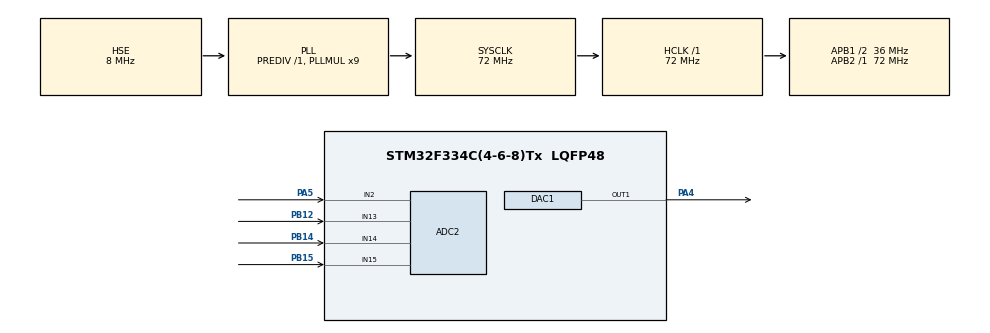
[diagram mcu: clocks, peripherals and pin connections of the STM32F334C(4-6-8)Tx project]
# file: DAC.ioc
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ADC2.Channel-0\#ChannelRegularConversion=ADC_CHANNEL_2
ADC2.NbrOfConversionFlag=1
ADC2.Offset-0\#ChannelRegularConversion=0
ADC2.OffsetNumber-0\#ChannelRegularConversion=ADC_OFFSET_NONE
ADC2.Rank-0\#ChannelRegularConversion=1
ADC2.SamplingTime-0\#ChannelRegularConversion=ADC_SAMPLETIME_1CYCLE_5
ADC2.SubFamily=STM32F334x8
Dma.ADC2.0.Direction=DMA_PERIPH_TO_MEMORY
Dma.ADC2.0.Instance=DMA1_Channel2
Dma.ADC2.0.MemDataAlignment=DMA_MDATAALIGN_HALFWORD
Dma.ADC2.0.MemInc=DMA_MINC_ENABLE
Dma.ADC2.0.Mode=DMA_NORMAL
Dma.ADC2.0.PeriphDataAlignment=DMA_PDATAALIGN_HALFWORD
Dma.ADC2.0.PeriphInc=DMA_PINC_DISABLE
Dma.ADC2.0.Priority=DMA_PRIORITY_HIGH
Dma.Request0=ADC2
Mcu.Family=STM32F3
Mcu.Name=STM32F334C(4-6-8)Tx
Mcu.Package=LQFP48
NVIC.DMA1_Channel2_IRQn=true\:0\:0\:false\:false\:true\:false
NVIC.PriorityGroup=NVIC_PRIORITYGROUP_0
PA13.GPIO_Label=SWDIO
PA13.Mode=Serial_Wire
PA13.Signal=SYS_JTMS-SWDIO
PA14.GPIO_Label=SWCLK
PA14.Mode=Serial_Wire
PA14.Signal=SYS_JTCK-SWCLK
PA4.Signal=COMP_DAC11_group
PA5.Mode=IN2-Single-Ended
PA5.Signal=ADC2_IN2
PB12.Mode=IN13-Single-Ended
PB12.Signal=ADC2_IN13
PB14.Mode=IN14-Single-Ended
PB14.Signal=ADC2_IN14
PB15.Mode=IN15-Single-Ended
PB15.Signal=ADC2_IN15
PF0\ /\ OSC_IN.GPIO_Label=PF0-OSC_IN
PF0\ /\ OSC_IN.Mode=HSE-External-Oscillator
PF0\ /\ OSC_IN.Signal=RCC_OSC_IN
PF1\ /\ OSC_OUT.Mode=HSE-External-Oscillator
PF1\ /\ OSC_OUT.Signal=RCC_OSC_OUT
ProjectManager.HeapSize=0x200
ProjectManager.StackSize=0x400
ProjectManager.TargetToolchain=EWARM V7
RCC.AHBFreq_Value=72000000
RCC.APB1CLKDivider=RCC_HCLK_DIV2
RCC.APB1Freq_Value=36000000
RCC.APB1TimFreq_Value=72000000
RCC.APB2Freq_Value=72000000
RCC.APB2TimFreq_Value=72000000
RCC.CortexFreq_Value=72000000
RCC.HCLKFreq_Value=72000000
RCC.HSE_VALUE=8000000
RCC.HSI_VALUE=8000000
RCC.LSE_VALUE=32768
RCC.PLLMUL=RCC_PLL_MUL9
RCC.PLLSourceVirtual=RCC_PLLSOURCE_HSE
RCC.SYSCLKFreq_VALUE=72000000
RCC.SYSCLKSourceVirtual=RCC_SYSCLKSOURCE_PLLCLK
SH.COMP_DAC11_group.0=DAC1_OUT1,DAC_OUT1
board=32F3348DISCOVERY

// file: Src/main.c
/**
  ******************************************************************************
  * @file           : main.c
  * @brief          : Main program body
  ******************************************************************************
  ** This notice applies to any and all portions of this file
  * that are not between comment pairs USER CODE BEGIN and
  * USER CODE END. Other portions of this file, whether
  * inserted by the user or by software development tools
  * are owned by their respective copyright owners.
  *
  * COPYRIGHT(c) 2019 STMicroelectronics
  *
  * Redistribution and use in source and binary forms, with or without modification,
  * are permitted provided that the following conditions are met:
  *   1. Redistributions of source code must retain the above copyright notice,
  *      this list of conditions and the following disclaimer.
  *   2. Redistributions in binary form must reproduce the above copyright notice,
  *      this list of conditions and the following disclaimer in the documentation
  *      and/or other materials provided with the distribution.
  *   3. Neither the name of STMicroelectronics nor the names of its contributors
  *      may be used to endorse or promote products derived from this software
  *      without specific prior written permission.
  *
  * THIS SOFTWARE IS PROVIDED BY THE COPYRIGHT HOLDERS AND CONTRIBUTORS "AS IS"
  * AND ANY EXPRESS OR IMPLIED WARRANTIES, INCLUDING, BUT NOT LIMITED TO, THE
  * IMPLIED WARRANTIES OF MERCHANTABILITY AND FITNESS FOR A PARTICULAR PURPOSE ARE
  * DISCLAIMED. IN NO EVENT SHALL THE COPYRIGHT HOLDER OR CONTRIBUTORS BE LIABLE
  * FOR ANY DIRECT, INDIRECT, INCIDENTAL, SPECIAL, EXEMPLARY, OR CONSEQUENTIAL
  * DAMAGES (INCLUDING, BUT NOT LIMITED TO, PROCUREMENT OF SUBSTITUTE GOODS OR
  * SERVICES; LOSS OF USE, DATA, OR PROFITS; OR BUSINESS INTERRUPTION) HOWEVER
  * CAUSED AND ON ANY THEORY OF LIABILITY, WHETHER IN CONTRACT, STRICT LIABILITY,
  * OR TORT (INCLUDING NEGLIGENCE OR OTHERWISE) ARISING IN ANY WAY OUT OF THE USE
  * OF THIS SOFTWARE, EVEN IF ADVISED OF THE POSSIBILITY OF SUCH DAMAGE.
  *
  ******************************************************************************
  */
#include "main.h"
#include "stm32f3xx_hal.h"

/* USER CODE BEGIN Includes */
// This test includes 6 parts:
// 1. Test DAC
// 2. Test ADC-DMA with Sampling
// 3. Test GPIO input interrupt
// 4. Test System Stick Timer
// 5. Test UART
// 6. Test SPI

/* USER CODE END Includes */

ADC_HandleTypeDef hadc2;
DMA_HandleTypeDef hdma_adc2;

DAC_HandleTypeDef hdac1;

/* USER CODE BEGIN PV */
/* Private variables ---------------------------------------------------------*/
uint16_t adcValue = 0;
uint32_t i = 0;
/* USER CODE END PV */

void SystemClock_Config(void);
static void MX_GPIO_Init(void);
static void MX_DMA_Init(void);
static void MX_DAC1_Init(void);
static void MX_ADC2_Init(void);

/* USER CODE BEGIN PFP */
/* Private function prototypes -----------------------------------------------*/

/* USER CODE END PFP */

/* USER CODE BEGIN 0 */
// Input voltage must be x100 of desired value
void SetCurVolt( uint16_t x100voltage){
    uint16_t setValue;

    // 0 to 4095 leads to 0V -> 3.3V
    // setValue = (uint16_t)voltage/100/3.3*4096;
    setValue = (uint16_t)(x100voltage*12.412);

    //(#) 12-bit right alignment using DAC_ALIGN_12B_R
    HAL_DAC_SetValue(&hdac1, DAC_CHANNEL_1, DAC_ALIGN_12B_R, setValue);
    //HAL_Delay(1);
}
/* USER CODE END 0 */

int main(void)
{

  /* MCU Configuration----------------------------------------------------------*/

  /* Reset of all peripherals, Initializes the Flash interface and the Systick. */
  HAL_Init();

  /* Configure the system clock */
  SystemClock_Config();

  /* Initialize all configured peripherals */
  MX_GPIO_Init();
  MX_DMA_Init();
  MX_DAC1_Init();
  MX_ADC2_Init();
  /* USER CODE BEGIN 2 */
    HAL_DAC_Start(&hdac1, DAC_CHANNEL_1);
  SetCurVolt(300);

  /* USER CODE END 2 */

  /* Infinite loop */
  while (1)
  {

  /* USER CODE BEGIN 3 */

	/*
    HAL_ADC_Start(&hadc2);
    HAL_ADC_PollForConversion(&hadc2, 100);
    adcValue = HAL_ADC_GetValue(&hadc2);
    HAL_DAC_Start(&hdac1, DAC_CHANNEL_1);
    HAL_DAC_SetValue(&hdac1, DAC_CHANNEL_1, DAC_ALIGN_12B_R, 4095);
	*/
	/*
    while(1){
      for (i = 0; i < 4096; i++){
        //(#) 12-bit right alignment using DAC_ALIGN_12B_R
            //HAL_DAC_SetValue(&hdac1, DAC_CHANNEL_1, DAC_ALIGN_12B_R, 4095);
            //HAL_Delay(1);
      }
    }
	*/
  }
  /* USER CODE END 3 */

}

void SystemClock_Config(void)
{

  RCC_OscInitTypeDef RCC_OscInitStruct;
  RCC_ClkInitTypeDef RCC_ClkInitStruct;
  RCC_PeriphCLKInitTypeDef PeriphClkInit;

    /**Initializes the CPU, AHB and APB busses clocks
    */
  RCC_OscInitStruct.OscillatorType = RCC_OSCILLATORTYPE_HSE;
  RCC_OscInitStruct.HSEState = RCC_HSE_ON;
  RCC_OscInitStruct.HSEPredivValue = RCC_HSE_PREDIV_DIV1;
  RCC_OscInitStruct.HSIState = RCC_HSI_ON;
  RCC_OscInitStruct.PLL.PLLState = RCC_PLL_ON;
  RCC_OscInitStruct.PLL.PLLSource = RCC_PLLSOURCE_HSE;
  RCC_OscInitStruct.PLL.PLLMUL = RCC_PLL_MUL9;
  if (HAL_RCC_OscConfig(&RCC_OscInitStruct) != HAL_OK)
  {
    _Error_Handler(__FILE__, __LINE__);
  }

    /**Initializes the CPU, AHB and APB busses clocks
    */
  RCC_ClkInitStruct.ClockType = RCC_CLOCKTYPE_HCLK|RCC_CLOCKTYPE_SYSCLK
                              |RCC_CLOCKTYPE_PCLK1|RCC_CLOCKTYPE_PCLK2;
  RCC_ClkInitStruct.SYSCLKSource = RCC_SYSCLKSOURCE_PLLCLK;
  RCC_ClkInitStruct.AHBCLKDivider = RCC_SYSCLK_DIV1;
  RCC_ClkInitStruct.APB1CLKDivider = RCC_HCLK_DIV2;
  RCC_ClkInitStruct.APB2CLKDivider = RCC_HCLK_DIV1;

  if (HAL_RCC_ClockConfig(&RCC_ClkInitStruct, FLASH_LATENCY_2) != HAL_OK)
  {
    _Error_Handler(__FILE__, __LINE__);
  }

  PeriphClkInit.PeriphClockSelection = RCC_PERIPHCLK_ADC12;
  PeriphClkInit.Adc12ClockSelection = RCC_ADC12PLLCLK_DIV1;
  if (HAL_RCCEx_PeriphCLKConfig(&PeriphClkInit) != HAL_OK)
  {
    _Error_Handler(__FILE__, __LINE__);
  }

    /**Configure the Systick interrupt time
    */
  HAL_SYSTICK_Config(HAL_RCC_GetHCLKFreq()/1000);

    /**Configure the Systick
    */
  HAL_SYSTICK_CLKSourceConfig(SYSTICK_CLKSOURCE_HCLK);

  /* SysTick_IRQn interrupt configuration */
  HAL_NVIC_SetPriority(SysTick_IRQn, 0, 0);
}

/* ADC2 init function */
static void MX_ADC2_Init(void)
{

  ADC_ChannelConfTypeDef sConfig;

    /**Common config
    */
  hadc2.Instance = ADC2;
  hadc2.Init.ClockPrescaler = ADC_CLOCK_ASYNC_DIV1;
  hadc2.Init.Resolution = ADC_RESOLUTION_12B;
  hadc2.Init.ScanConvMode = ADC_SCAN_DISABLE;
  hadc2.Init.ContinuousConvMode = DISABLE;
  hadc2.Init.DiscontinuousConvMode = DISABLE;
  hadc2.Init.ExternalTrigConvEdge = ADC_EXTERNALTRIGCONVEDGE_NONE;
  hadc2.Init.ExternalTrigConv = ADC_SOFTWARE_START;
  hadc2.Init.DataAlign = ADC_DATAALIGN_RIGHT;
  hadc2.Init.NbrOfConversion = 1;
  hadc2.Init.DMAContinuousRequests = DISABLE;
  hadc2.Init.EOCSelection = ADC_EOC_SINGLE_CONV;
  hadc2.Init.LowPowerAutoWait = DISABLE;
  hadc2.Init.Overrun = ADC_OVR_DATA_OVERWRITTEN;
  if (HAL_ADC_Init(&hadc2) != HAL_OK)
  {
    _Error_Handler(__FILE__, __LINE__);
  }

    /**Configure Regular Channel
    */
  sConfig.Channel = ADC_CHANNEL_2;
  sConfig.Rank = ADC_REGULAR_RANK_1;
  sConfig.SingleDiff = ADC_SINGLE_ENDED;
  sConfig.SamplingTime = ADC_SAMPLETIME_1CYCLE_5;
  sConfig.OffsetNumber = ADC_OFFSET_NONE;
  sConfig.Offset = 0;
  if (HAL_ADC_ConfigChannel(&hadc2, &sConfig) != HAL_OK)
  {
    _Error_Handler(__FILE__, __LINE__);
  }

}

/* DAC1 init function */
static void MX_DAC1_Init(void)
{

  DAC_ChannelConfTypeDef sConfig;

    /**DAC Initialization
    */
  hdac1.Instance = DAC1;
  if (HAL_DAC_Init(&hdac1) != HAL_OK)
  {
    _Error_Handler(__FILE__, __LINE__);
  }

    /**DAC channel OUT1 config
    */
  sConfig.DAC_Trigger = DAC_TRIGGER_NONE;
  sConfig.DAC_OutputBuffer = DAC_OUTPUTBUFFER_ENABLE;
  if (HAL_DAC_ConfigChannel(&hdac1, &sConfig, DAC_CHANNEL_1) != HAL_OK)
  {
    _Error_Handler(__FILE__, __LINE__);
  }

}

static void MX_DMA_Init(void)
{
  /* DMA controller clock enable */
  __HAL_RCC_DMA1_CLK_ENABLE();

  /* DMA interrupt init */
  /* DMA1_Channel2_IRQn interrupt configuration */
  HAL_NVIC_SetPriority(DMA1_Channel2_IRQn, 0, 0);
  HAL_NVIC_EnableIRQ(DMA1_Channel2_IRQn);

}

/** Configure pins as
        * Analog
        * Input
        * Output
        * EVENT_OUT
        * EXTI
*/
static void MX_GPIO_Init(void)
{

  /* GPIO Ports Clock Enable */
  __HAL_RCC_GPIOF_CLK_ENABLE();
  __HAL_RCC_GPIOA_CLK_ENABLE();
  __HAL_RCC_GPIOB_CLK_ENABLE();

}

void _Error_Handler(char *file, int line)
{
  while(1)
  {
  }
}

/************************ (C) COPYRIGHT STMicroelectronics *****END OF FILE****/
